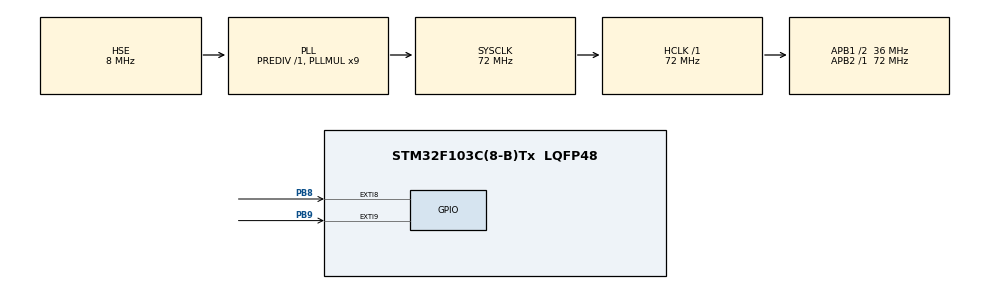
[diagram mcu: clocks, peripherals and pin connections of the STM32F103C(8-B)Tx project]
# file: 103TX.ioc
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Mcu.Family=STM32F1
RCC.PLLSourceVirtual=RCC_PLLSOURCE_HSE
PD1-OSC_OUT.Mode=HSE-External-Oscillator
PD0-OSC_IN.Signal=RCC_OSC_IN
RCC.APB1CLKDivider=RCC_HCLK_DIV2
RCC.SYSCLKSource=RCC_SYSCLKSOURCE_PLLCLK
ProjectManager.StackSize=0x400
PD1-OSC_OUT.Signal=RCC_OSC_OUT
PA13.Signal=SYS_JTMS-SWDIO
PB8.GPIO_ModeDefaultEXTI=GPIO_MODE_IT_FALLING
ProjectManager.TargetToolchain=MDK-ARM V5.27
RCC.HCLKFreq_Value=72000000
RCC.APB2TimFreq_Value=72000000
PB9.GPIO_ModeDefaultEXTI=GPIO_MODE_IT_FALLING
RCC.USBFreq_Value=72000000
TIM4.Prescaler=35
RCC.AHBFreq_Value=72000000
PD0-OSC_IN.Mode=HSE-External-Oscillator
board=custom
RCC.PLLMUL=RCC_PLL_MUL9
RCC.APB2Freq_Value=72000000
PA14.Mode=Serial_Wire
TIM4.Period=999
PA13.Mode=Serial_Wire
Mcu.Name=STM32F103C(8-B)Tx
RCC.SYSCLKFreq_VALUE=72000000
Mcu.Package=LQFP48
PB9.Signal=GPXTI9
NVIC.EXTI9_5_IRQn=true\:0\:0\:false\:false\:true\:true\:true
PA14.Signal=SYS_JTCK-SWCLK
ProjectManager.HeapSize=0x400
VP_TIM4_VS_ClockSourceINT.Mode=Internal
NVIC.PriorityGroup=NVIC_PRIORITYGROUP_4
RCC.APB1TimFreq_Value=72000000
PB8.Signal=GPXTI8
NVIC.TIM4_IRQn=true\:0\:0\:false\:false\:true\:true\:true
RCC.APB1Freq_Value=36000000

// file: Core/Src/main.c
/* USER CODE BEGIN Header */
/**
  ******************************************************************************
  * @file           : main.c
  * @brief          : Main program body
  ******************************************************************************
  * @attention
  *
  * <h2><center>&copy; Copyright (c) 2020 STMicroelectronics.
  * All rights reserved.</center></h2>
  *
  * This software component is licensed by ST under BSD 3-Clause license,
  * the "License"; You may not use this file except in compliance with the
  * License. You may obtain a copy of the License at:
  *                        opensource.org/licenses/BSD-3-Clause
  *
  ******************************************************************************
  */
/* USER CODE END Header */
#include "main.h"
#include "tim.h"
#include "gpio.h"

/* USER CODE BEGIN Includes */
#include "bsp_one_line.h"
#include "app_one_line.h"
/* USER CODE END Includes */

void SystemClock_Config(void);

int main(void)
{

  /* MCU Configuration--------------------------------------------------------*/

  /* Reset of all peripherals, Initializes the Flash interface and the Systick. */
  HAL_Init();

  /* Configure the system clock */
  SystemClock_Config();

  /* Initialize all configured peripherals */
  MX_GPIO_Init();
  MX_TIM4_Init();
  /* USER CODE BEGIN 2 */
    __HAL_TIM_ENABLE_IT(&htim4, TIM_IT_UPDATE);
    HAL_TIM_Base_Start_IT(&htim4);

    one_line_send("1234567890abcdefghijklmn", 24);

  /* USER CODE END 2 */

  /* Infinite loop */
  /* USER CODE BEGIN WHILE */
  while (1)
  {
        OneLineTest();

    /* USER CODE END WHILE */

  }
}

void SystemClock_Config(void)
{
  RCC_OscInitTypeDef RCC_OscInitStruct = {0};
  RCC_ClkInitTypeDef RCC_ClkInitStruct = {0};

  /** Initializes the RCC Oscillators according to the specified parameters
  * in the RCC_OscInitTypeDef structure.
  */
  RCC_OscInitStruct.OscillatorType = RCC_OSCILLATORTYPE_HSE;
  RCC_OscInitStruct.HSEState = RCC_HSE_ON;
  RCC_OscInitStruct.HSEPredivValue = RCC_HSE_PREDIV_DIV1;
  RCC_OscInitStruct.HSIState = RCC_HSI_ON;
  RCC_OscInitStruct.PLL.PLLState = RCC_PLL_ON;
  RCC_OscInitStruct.PLL.PLLSource = RCC_PLLSOURCE_HSE;
  RCC_OscInitStruct.PLL.PLLMUL = RCC_PLL_MUL9;
  if (HAL_RCC_OscConfig(&RCC_OscInitStruct) != HAL_OK)
  {
    Error_Handler();
  }
  /** Initializes the CPU, AHB and APB buses clocks
  */
  RCC_ClkInitStruct.ClockType = RCC_CLOCKTYPE_HCLK|RCC_CLOCKTYPE_SYSCLK
                              |RCC_CLOCKTYPE_PCLK1|RCC_CLOCKTYPE_PCLK2;
  RCC_ClkInitStruct.SYSCLKSource = RCC_SYSCLKSOURCE_PLLCLK;
  RCC_ClkInitStruct.AHBCLKDivider = RCC_SYSCLK_DIV1;
  RCC_ClkInitStruct.APB1CLKDivider = RCC_HCLK_DIV2;
  RCC_ClkInitStruct.APB2CLKDivider = RCC_HCLK_DIV1;

  if (HAL_RCC_ClockConfig(&RCC_ClkInitStruct, FLASH_LATENCY_2) != HAL_OK)
  {
    Error_Handler();
  }
}

void Error_Handler(void)
{
}

/************************ (C) COPYRIGHT STMicroelectronics *****END OF FILE****/
